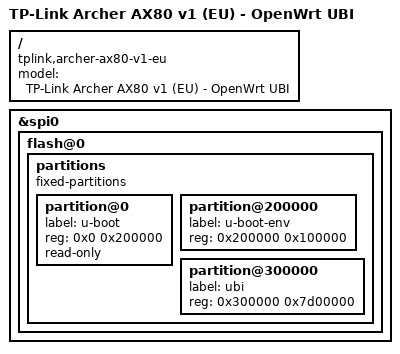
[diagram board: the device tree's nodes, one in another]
/dts-v1/;

#include "mt7986b-tplink-archer-ax80-v1-eu-common.dtsi"

 / {
	compatible = "tplink,archer-ax80-v1-eu", "mediatek,mt7986b";
	model = "TP-Link Archer AX80 v1 (EU) - OpenWrt UBI";
 };

&spi0 {
	flash@0 {
		partitions {
			compatible = "fixed-partitions";
			#address-cells = <1>;
			#size-cells = <1>;

			partition@0 {
				label = "u-boot";
				reg = <0x0 0x200000>;
				read-only;
			};

			partition@200000 {
				label = "u-boot-env";
				reg = <0x200000 0x100000>;
			};

			partition@300000 {
				label = "ubi";
				reg = <0x300000 0x7d00000>;
			};
		};
	};
};
